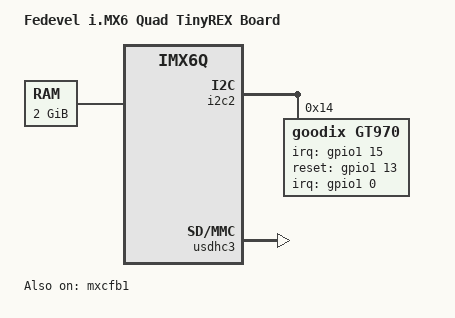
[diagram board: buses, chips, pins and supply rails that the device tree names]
/*
 * Copyright (C) 2015 Voipac.
 *
 * The code contained herein is licensed under the GNU General Public
 * License. You may obtain a copy of the GNU General Public License
 * Version 2 or later at the following locations:
 *
 * http://www.opensource.org/licenses/gpl-license.html
 * http://www.gnu.org/copyleft/gpl.html
 */

/dts-v1/;

#include "imx6q.dtsi"
#include "imx6qdl-tinyrex.dtsi"

/ {
	model = "Fedevel i.MX6 Quad TinyREX Board";
	compatible = "fsl,imx6q-tinyrex", "fsl,imx6q";

	memory {
		reg = <0x10000000 0x80000000>;
	};
};

&i2c2 {
	/* Goodix 970 touchscreen controller */
gt970: gt970@14 {
        compatible = "goodix,gt970";
        reg = <0x14>;
        interrupt-parent = <&gpio1>;
        interrupts = <0 0>;

        irq-gpios = <&gpio1 15 0>;
        reset-gpios = <&gpio1 13 0>;
    };
};

&mxcfb1 {
	status = "okay";
};

&mxcfb2 {
	status = "disabled";
};

&mxcfb3 {
	status = "disabled";
};

&mxcfb4 {
	status = "disabled";
};

&sata {
	status = "disabled";
};

&usdhc3 {
	status = "okay";
};
